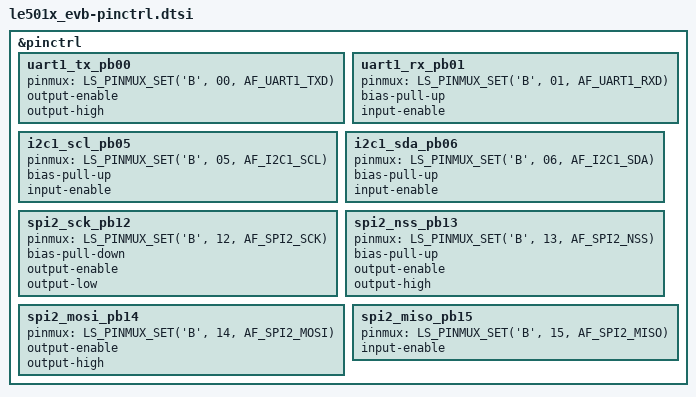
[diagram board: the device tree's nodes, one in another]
/*
 * Copyright (c) 2023 Linkedsemi
 *
 * SPDX-License-Identifier: Apache-2.0
 */

#include <linkedsemi/le501x.dtsi>
#include <zephyr/dt-bindings/pinctrl/ls-pinctrl.h>

&pinctrl {
	/* UART1 */
	/omit-if-no-ref/uart1_tx_pb00: uart1_tx_pb00 {
		pinmux = <LS_PINMUX_SET('B', 00, AF_UART1_TXD)>;
        output-enable;
        output-high;

	};
	/omit-if-no-ref/uart1_rx_pb01: uart1_rx_pb01 {
		pinmux = <LS_PINMUX_SET('B', 01, AF_UART1_RXD)>;
        bias-pull-up;
		input-enable;
	};

	/* I2C1 */
	/omit-if-no-ref/i2c1_scl_pb05: i2c1_scl_pb05 {
		pinmux = <LS_PINMUX_SET('B', 05, AF_I2C1_SCL)>;
		bias-pull-up;
		input-enable;
	};
	/omit-if-no-ref/i2c1_sda_pb06: i2c1_sda_pb06 {
		pinmux = <LS_PINMUX_SET('B', 06, AF_I2C1_SDA)>;
		bias-pull-up;
		input-enable;
	};

	/* SPI2 */
    /omit-if-no-ref/spi2_sck_pb12: spi2_sck_pb12 {
		pinmux = <LS_PINMUX_SET('B', 12, AF_SPI2_SCK)>;
        bias-pull-down;
		output-enable;
        output-low;
	};

    /omit-if-no-ref/ spi2_nss_pb13: spi2_nss_pb13 {
		pinmux = <LS_PINMUX_SET('B', 13, AF_SPI2_NSS)>;
		bias-pull-up;
        output-enable;
        output-high;
	};

    /omit-if-no-ref/spi2_mosi_pb14: spi2_mosi_pb14 {
        pinmux = <LS_PINMUX_SET('B', 14, AF_SPI2_MOSI)>;
        output-enable;
        output-high;
    };

    /omit-if-no-ref/ spi2_miso_pb15: spi2_miso_pb15 {
        pinmux = <LS_PINMUX_SET('B', 15, AF_SPI2_MISO)>;
        input-enable;
    };
};
